AUTOSAR XML (schema 4-2-1)
standard types defined: float32, float64, sint8, sint16, sint32, uint8, uint16, uint32, boolean, dtRef_VOID, Float32, Boolean, UInt32, UInt8, UInt16
package /FoundationPkg/FoundationArchitecturePkg
  5 x constant specification:
    iColumnData_ColumnTorque_Init: value-spec={short-label=iColumnData_ColumnTorque_Init, fields=[0 Nm_Unit, 0 NmPerSec_Unit, 0]}
    iColumnData_SteeringPositionLower_Init: value-spec={short-label=iColumnData_SteeringPositionLower_Init, fields=[0 Degrees_Unit, 0]}
    iColumnData_ColumnVelocity_Init: value-spec={short-label=iColumnData_ColumnVelocity_Init, fields=[0 RevsPerSec_Unit, 0 RevsPerSec_Unit, 0]}
    iColumnData_SteeringPositionUpper_Init: value-spec={short-label=iColumnData_SteeringPositionUpper_Init, fields=[0 Degrees_Unit, 0]}
    iColumnData_ColumnPositionLower_Init: value-spec={short-label=iColumnData_ColumnPositionLower_Init, fields=[0 Degrees_Unit, 0]}
  sender receiver interface iColumnData
    5 x data, all with sw-calibration-access=READ-ONLY:
      ColumnTorque: type=tInputTorque, init-value=constant-reference=iColumnData_ColumnTorque_Init
      SteeringPositionLower: type=tColumnPosition, init-value=constant-reference=iColumnData_SteeringPositionLower_Init
      ColumnVelocity: type=tColumnVelocity, init-value=constant-reference=iColumnData_ColumnVelocity_Init
      SteeringPositionUpper: type=tColumnPosition, init-value=constant-reference=iColumnData_SteeringPositionUpper_Init
      ColumnPositionLower: type=tMechanicalMotorPosition, init-value=constant-reference=iColumnData_ColumnPositionLower_Init
  constant specification iTorque_Torque_Init: value-spec={short-label=iTorque_Torque_Init, fields=[0 Nm_Unit, 0 NmPerSec_Unit, 0]}
  sender receiver interface iTorque
    data Torque: sw-calibration-access=READ-ONLY, type=tInputTorque, init-value=constant-reference=iTorque_Torque_Init
  constant specification iAngle_Angle_Init: value-spec={short-label=iAngle_Angle_Init, fields=[0 Degrees_Unit, 0]}
  sender receiver interface iAngle
    data Angle: sw-calibration-access=READ-ONLY, type=tSensorAngle, init-value=constant-reference=iAngle_Angle_Init
  constant specification iPinionData_PinionPosition_Init: value-spec={short-label=iPinionData_PinionPosition_Init, fields=[0 Degrees_Unit, 0]}
  constant specification iPinionData_PinionVelocity_Init: value-spec={short-label=iPinionData_PinionVelocity_Init, fields=[0 RevsPerSec_Unit, 0 RevsPerSec_Unit, 0]}
  sender receiver interface iPinionData
    data PinionPosition: sw-calibration-access=READ-ONLY, type=tPinionPosition, init-value=constant-reference=iPinionData_PinionPosition_Init
    data PinionVelocity: sw-calibration-access=READ-ONLY, type=tColumnVelocity, init-value=constant-reference=iPinionData_PinionVelocity_Init
  constant specification iVehicleData_VehicleSpeed_Init: value-spec={short-label=iVehicleData_VehicleSpeed_Init, fields=[0 Kph_Unit, 0, 0]}
  constant specification iVehicleData_SteeringAngle_Init: value-spec={short-label=iVehicleData_SteeringAngle_Init, fields=[0 Degrees_Unit, 0]}
  sender receiver interface iVehicleData
    data VehicleSpeed: sw-calibration-access=READ-ONLY, type=tVehicleSpd, init-value=constant-reference=iVehicleData_VehicleSpeed_Init
    data SteeringAngle: sw-calibration-access=READ-ONLY, type=tColumnPosition, init-value=constant-reference=iVehicleData_SteeringAngle_Init
  5 x constant specification:
    iTuneData_VEHICLE_SPEED_BREAKPOINTS_Init: value-spec=[0.0, 5.0, 10.0, 15.0, 25.0, 35.0, 50.0, 70.0, 90.0, 120.0, 150.0, 190.0]
    iTuneData_TIME_SFB_Init: value-spec=20
    iTuneData_ANGLE_MEASUREMENT_RANGE_Init: value-spec=1800.0
    iTuneData_MAX_NVM_WRITE_WAIT_TIME_Init: value-spec=100
    iTuneData_MAX_NVM_WRITE_ATTEMPTS_Init: value-spec=3
  parameter interface iTuneData
    5 x parameter data prototype, all with sw-addr-method=VehicleTune, sw-calibration-access=READ-WRITE:
      VEHICLE_SPEED_BREAKPOINTS: category=ARRAY, type=tVspdBkpts_0_0_to_255_0, init-value=constant-reference=iTuneData_VEHICLE_SPEED_BREAKPOINTS_Init
      TIME_SFB: category=VALUE, type=ms_20_to_20, init-value=constant-reference=iTuneData_TIME_SFB_Init
      ANGLE_MEASUREMENT_RANGE: category=VALUE, type=Degrees_0_0_to_1800_0, init-value=constant-reference=iTuneData_ANGLE_MEASUREMENT_RANGE_Init
      MAX_NVM_WRITE_WAIT_TIME: category=VALUE, type=ms, init-value=constant-reference=iTuneData_MAX_NVM_WRITE_WAIT_TIME_Init  # Time to wait for NVM write to complete
      MAX_NVM_WRITE_ATTEMPTS: category=VALUE, type=UInt8, init-value=constant-reference=iTuneData_MAX_NVM_WRITE_ATTEMPTS_Init  # Maximum number of times to attempt NVM write.
  client server interface iRack
    8 x operation:
      getMaxPhysicalAssist
        arg maxPhysicalAssist: type=Nm, direction=OUT
      initialisationColumnAngle
        arg pinionAngle: type=Degrees, direction=IN
      translateColumnAngleToRackPosition
        arg pinionAngle: type=Degrees, direction=IN
        arg rackPosition: type=mm, direction=OUT
      translateColumnTorqueToRackForce
        arg columnTorque: type=Nm, direction=IN
        arg rackForce: type=kN, direction=OUT
      translateRackPositionToColumnAngle
        arg rackPosition: type=mm, direction=IN
        arg columnAngle: type=Degrees, direction=OUT
      translateRackForceToColumnTorque
        arg rackForce: type=kN, direction=IN
        arg columnTorque: type=Nm, direction=OUT
      translateColumnVelocityToRackVelocity
        arg columnVelocity: type=DegreesPerSec, direction=IN
        arg rackVelocity: type=mmPerSec, direction=OUT
      translateRackVelocityToColumnVelocity
        arg rackVelocity: type=mmPerSec, direction=IN
        arg columnVelocity: type=DegreesPerSec, direction=OUT
  constant specification iStraightAheadOffset_StraightAheadOffset_Init: value-spec={short-label=iStraightAheadOffset_StraightAheadOffset_Init, fields=[0 Degrees_Unit, 0]}
  sender receiver interface iStraightAheadOffset
    data StraightAheadOffset: sw-calibration-access=READ-ONLY, type=tStraightAheadOffset, init-value=constant-reference=iStraightAheadOffset_StraightAheadOffset_Init
package /FoundationPkg/FoundationArchitecturePkg/FoundationEpsAbstractionPkg
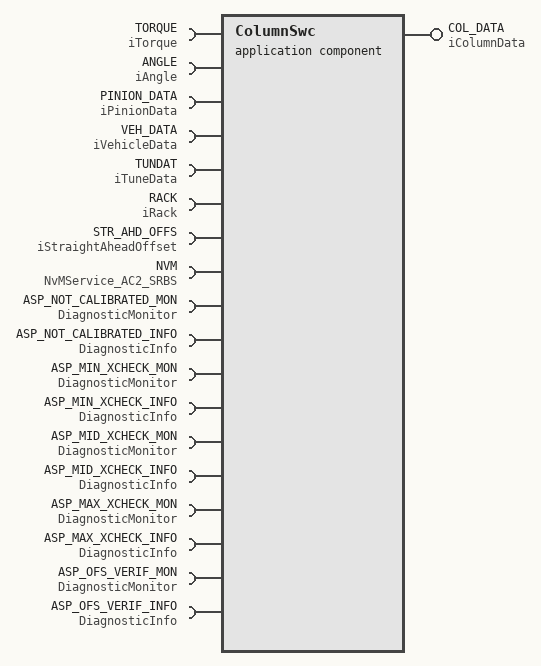
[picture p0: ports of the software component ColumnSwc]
  application sw component type ColumnSwc  # Model of the EPS steering column producing the column torque, positionand velocitysignals to the EPS system. The model shall take into account the physical characteristics of the steering column such as the torsion bar where they impact the output signals.
    provide port COL_DATA: provided-interface=iColumnData  # Output column data (torque, position and velocity)
      provided-com-specs:
        data-element=ColumnTorque, init-value=constant-reference=iColumnData_ColumnTorque_Init
        data-element=SteeringPositionLower, init-value=constant-reference=iColumnData_SteeringPositionLower_Init
        data-element=ColumnVelocity, init-value=constant-reference=iColumnData_ColumnVelocity_Init
        data-element=SteeringPositionUpper, init-value=constant-reference=iColumnData_SteeringPositionUpper_Init
        data-element=ColumnPositionLower, init-value=constant-reference=iColumnData_ColumnPositionLower_Init
    18 x require port:
      TORQUE: nonqueued-receiver-com-spec{data-element=Torque, init-value=constant-reference=iTorque_Torque_Init}, required-interface=iTorque  # Torque data received from the column torque sensor.
      ANGLE: nonqueued-receiver-com-spec{data-element=Angle, init-value=constant-reference=iAngle_Angle_Init}, required-interface=iAngle  # Angle data received from the column angle sensor.
      PINION_DATA: required-interface=iPinionData  # Data for the pinion position derived from the motor position
        required-com-specs:
          data-element=PinionPosition, init-value=constant-reference=iPinionData_PinionPosition_Init
          data-element=PinionVelocity, init-value=constant-reference=iPinionData_PinionVelocity_Init
      VEH_DATA: required-interface=iVehicleData  # Data regarding the vehicle dynamic state (speed, steering angle derived from the wheel speeds etc).
        required-com-specs:
          data-element=VehicleSpeed, init-value=constant-reference=iVehicleData_VehicleSpeed_Init
          data-element=SteeringAngle, init-value=constant-reference=iVehicleData_SteeringAngle_Init
      TUNDAT: required-interface=iTuneData
        required-com-specs:
          init-value=constant-reference=iTuneData_VEHICLE_SPEED_BREAKPOINTS_Init, parameter=VEHICLE_SPEED_BREAKPOINTS
          init-value=constant-reference=iTuneData_TIME_SFB_Init, parameter=TIME_SFB
          init-value=constant-reference=iTuneData_ANGLE_MEASUREMENT_RANGE_Init, parameter=ANGLE_MEASUREMENT_RANGE
          init-value=constant-reference=iTuneData_MAX_NVM_WRITE_WAIT_TIME_Init, parameter=MAX_NVM_WRITE_WAIT_TIME
          init-value=constant-reference=iTuneData_MAX_NVM_WRITE_ATTEMPTS_Init, parameter=MAX_NVM_WRITE_ATTEMPTS
      RACK: required-interface=iRack  # Set the initial column angle at startup.
      STR_AHD_OFFS: nonqueued-receiver-com-spec{data-element=StraightAheadOffset, init-value=constant-reference=iStraightAheadOffset_StraightAheadOffset_Init}, required-interface=iStraightAheadOffset  # Offset between the angle provided by the column angle sensor and the vehicle straight ahead position.
      NVM: required-interface=NvMService_AC2_SRBS
      ASP_NOT_CALIBRATED_MON: required-interface=DiagnosticMonitor
      ASP_NOT_CALIBRATED_INFO: required-interface=DiagnosticInfo
      ASP_MIN_XCHECK_MON: required-interface=DiagnosticMonitor
      ASP_MIN_XCHECK_INFO: required-interface=DiagnosticInfo
      ASP_MID_XCHECK_MON: required-interface=DiagnosticMonitor
      ASP_MID_XCHECK_INFO: required-interface=DiagnosticInfo
      ASP_MAX_XCHECK_MON: required-interface=DiagnosticMonitor
      ASP_MAX_XCHECK_INFO: required-interface=DiagnosticInfo
      ASP_OFS_VERIF_MON: required-interface=DiagnosticMonitor
      ASP_OFS_VERIF_INFO: required-interface=DiagnosticInfo
    behavior ColumnSwc_IB: data-type-mapping=MappingSet, handle-termination-and-restart=NO-SUPPORT
      ar-typed-per-instance-memorys:
        data ColumnNvm: category=STRUCTURE, type=tColumnNvm
      4 x timing event:
        Event_calculateColumnTorque: start-on-event=ColumnSwc_calculateColumnTorque, period=0.001
        Event_calculateColumnAngle: start-on-event=ColumnSwc_calculateColumnAngle, period=0.001
        Event_calculateColumnVelocity: start-on-event=ColumnSwc_calculateColumnVelocity, period=0.001
        Event_verifyAbsoluteSteeringPosition: start-on-event=ColumnSwc_verifyAbsoluteSteeringPosition, period=0.004
      init event Event_initialiser_Init: start-on-event=ColumnSwc_initialiser
      implicit-inter-runnable-variables:
        9 x data:
          SteeringPositionLower_Value: type=Degrees, init-value=constant-reference=SteeringPositionLower_Value_Init
          SteeringPositionLower_Qf: type=tQualityFactor, init-value=constant-reference=SteeringPositionLower_Qf_Init
          AspVerificationStatus: sw-calibration-access=READ-ONLY, type=tAspVerificationSts, init-value=constant-reference=ColumnSwc_AspVerificationStatus_Init
          ColumnTorque_Value: type=Nm, init-value=constant-reference=ColumnTorque_Value_Init
          ColumnTorque_Derivative: type=NmPerSec, init-value=constant-reference=ColumnTorque_Derivative_Init
          ColumnTorque_Qf: type=tQualityFactor, init-value=constant-reference=ColumnTorque_Qf_Init
          ColumnVelocity_Filtered: type=RevsPerSec, init-value=constant-reference=ColumnVelocity_Filtered_Init
          ColumnVelocity_Unfiltered: type=RevsPerSec, init-value=constant-reference=ColumnVelocity_Unfiltered_Init
          ColumnVelocity_Qf: type=tQualityFactor, init-value=constant-reference=ColumnVelocity_Qf_Init
      per-instance-parameters:
        12 x parameter data prototype, all with category=VALUE, sw-addr-method=VehicleTune, sw-calibration-access=READ-WRITE:
          TBAR_STIFFNESS: type=NmPerDegree_0_1_to_10_0, init-value=constant-reference=LocalCalibration_TBAR_STIFFNESS_Init
          SIGNAL_LATENCY_COMPENSATION_GAIN: type=Float32_n3_0_to_3_0, init-value=constant-reference=LocalCalibration_SIGNAL_LATENCY_COMPENSATION_GAIN_Init
          INITIAL_SP_TORQUE_THRESHOLD: type=Nm_0_to_10, init-value=constant-reference=LocalCalibration_INITIAL_SP_TORQUE_THRESHOLD_Init
          INITIAL_SP_COLUMN_VELOCITY_THRESHOLD: type=RevsPerSec_0_to_100, init-value=constant-reference=LocalCalibration_INITIAL_SP_COLUMN_VELOCITY_THRESHOLD_Init
          SP_VERIFICATION_NEGATE_THRESHOLD: type=Degrees_0_to_15, init-value=constant-reference=LocalCalibration_SP_VERIFICATION_NEGATE_THRESHOLD_Init
          SP_VERIFICATION_AFFIRM_THRESHOLD: type=Degrees_0_to_15, init-value=constant-reference=LocalCalibration_SP_VERIFICATION_AFFIRM_THRESHOLD_Init
          PRIMARY_ASP_SOURCE: type=tPrimaryAspSource, init-value=constant-reference=LocalCalibration_PRIMARY_ASP_SOURCE_Init  # Which sensor is to be used as primary source for ASP.
          ANGLE_SENSOR_POSITION: type=tAngleSensorPosition, init-value=constant-reference=LocalCalibration_ANGLE_SENSOR_POSITION_Init  # Location of the angle sensor, above or below the torsion bar.
          SA_VERIFY_NUM_INTGL_INST: type=UInt16_1_to_100, init-value=constant-reference=LocalCalibration_SA_VERIFY_NUM_INTGL_INST_Init  # Tumber of learning instances to be used for averaging the deviation between calculated (based on sensor signals) and estimated (based on wheel speeds) .
          SA_VERIFY_STORED_POSN_DEV_THD: type=Degrees_0_to_1000, init-value=constant-reference=LocalCalibration_SA_VERIFY_STORED_POSN_DEV_THD_Init  # Threshold to check last stored ASP with key-on ASP to detect key-off steering.
          SA_VERIFY_AVRG_DEV_THD: type=Degrees_0_to_1000, init-value=constant-reference=LocalCalibration_SA_VERIFY_AVRG_DEV_THD_Init  # Threshold to check last stored ASP with key-on ASP to detect key-off steering.
          ASP_OFS_VERIFICATION_ACTVD: type=Boolean, init-value=constant-reference=LocalCalibration_ASP_OFS_VERIFICATION_ACTVD_Init
      5 x runnable:
        ColumnSwc_calculateColumnTorque: symbol=Column_calculateColumnTorque  # Calculate the column torque from the column sensor torque input.
          data-read-access:
            access R_TORQUE_Torque: accessed-variable=TORQUE.Torque
          data-write-access:
            access W_COL_DATA_ColumnTorque: accessed-variable=COL_DATA.ColumnTorque
          parameter access TIME_SFB: accessed-parameter=TUNDAT.TIME_SFB
          written-local-variables:
            access WV_ColumnTorque_Value: accessed-variable=ColumnTorque_Value
            access WV_ColumnTorque_Derivative: accessed-variable=ColumnTorque_Derivative
            access WV_ColumnTorque_Qf: accessed-variable=ColumnTorque_Qf
        ColumnSwc_calculateColumnAngle: symbol=Column_calculateColumnAngle  # Column offsets the raw angle received from the angle sensor with the calibrated straight ahead position to provide an absolute steering position. Column torque is used to compensate for torsion bar deflection. A cross check is made between the column position determined from the motor position sensor and the value from the column sensor to provide an ASIL D ASP value.
          data-read-access:
            access R_PINION_DATA_PinionPosition: accessed-variable=PINION_DATA.PinionPosition
            access R_ANGLE_Angle: accessed-variable=ANGLE.Angle
            access R_STR_AHD_OFFS_StraightAheadOffset: accessed-variable=STR_AHD_OFFS.StraightAheadOffset
          data-write-access:
            access W_COL_DATA_SteeringPositionLower: accessed-variable=COL_DATA.SteeringPositionLower
            access W_COL_DATA_SteeringPositionUpper: accessed-variable=COL_DATA.SteeringPositionUpper
            access W_COL_DATA_ColumnPositionLower: accessed-variable=COL_DATA.ColumnPositionLower
          4 x parameter access:
            TBAR_STIFFNESS: accessed-parameter=TBAR_STIFFNESS
            ANGLE_MEASUREMENT_RANGE: accessed-parameter=TUNDAT.ANGLE_MEASUREMENT_RANGE
            PRIMARY_ASP_SOURCE: accessed-parameter=PRIMARY_ASP_SOURCE
            ANGLE_SENSOR_POSITION: accessed-parameter=ANGLE_SENSOR_POSITION
          read-local-variables:
            4 x access:
              RV_AspVerificationStatus: accessed-variable=AspVerificationStatus
              RV_ColumnTorque_Value: accessed-variable=ColumnTorque_Value
              RV_ColumnTorque_Derivative: accessed-variable=ColumnTorque_Derivative
              RV_ColumnTorque_Qf: accessed-variable=ColumnTorque_Qf
          5 x sync call:
            Call_RACK_initialisationColumnAngle: operation=RACK.initialisationColumnAngle
            Call_ASP_NOT_CALIBRATED_SetEventStatus: operation=ASP_NOT_CALIBRATED_MON.SetEventStatus
            Call_ASP_NOT_CALIBRATED_ResetEventStatus: operation=ASP_NOT_CALIBRATED_MON.ResetEventDebounceStatus
            Call_ASP_NOT_CALIBRATED_GetEventStatus: operation=ASP_NOT_CALIBRATED_INFO.GetEventStatus
            Call_ASP_NOT_CALIBRATED_GetEventFailed: operation=ASP_NOT_CALIBRATED_INFO.GetEventFailed
          written-local-variables:
            access WV_SteeringPositionLower_Value: accessed-variable=SteeringPositionLower_Value
            access WV_SteeringPositionLower_Qf: accessed-variable=SteeringPositionLower_Qf
        ColumnSwc_calculateColumnVelocity: symbol=Column_calculateColumnVelocity  # Column Velocity is a read through of the pinion velocity.
          data-read-access:
            access R_PINION_DATA_PinionVelocity: accessed-variable=PINION_DATA.PinionVelocity
          data-write-access:
            access W_COL_DATA_ColumnVelocity: accessed-variable=COL_DATA.ColumnVelocity
          written-local-variables:
            access WV_ColumnVelocity_Filtered: accessed-variable=ColumnVelocity_Filtered
            access WV_ColumnVelocity_Unfiltered: accessed-variable=ColumnVelocity_Unfiltered
            access WV_ColumnVelocity_Qf: accessed-variable=ColumnVelocity_Qf
        ColumnSwc_verifyAbsoluteSteeringPosition: symbol=Column_verifyAbsoluteSteeringPosition  # Perform a cross check between the absolute steering position produced from the column angle sensor against the column angle derived from the motor position sensor. Report the validity of the cross check to the calculate column angle runnable.
          data-read-access:
            access R_PINION_DATA_PinionPosition: accessed-variable=PINION_DATA.PinionPosition
            access R_VEH_DATA_SteeringAngle: accessed-variable=VEH_DATA.SteeringAngle
            access R_ANGLE_Angle: accessed-variable=ANGLE.Angle
          9 x parameter access:
            INITIAL_SP_COLUMN_VELOCITY_THRESHOLD: accessed-parameter=INITIAL_SP_COLUMN_VELOCITY_THRESHOLD
            INITIAL_SP_TORQUE_THRESHOLD: accessed-parameter=INITIAL_SP_TORQUE_THRESHOLD
            SIGNAL_LATENCY_COMPENSATION_GAIN: accessed-parameter=SIGNAL_LATENCY_COMPENSATION_GAIN
            SP_VERIFICATION_AFFIRM_THRESHOLD: accessed-parameter=SP_VERIFICATION_AFFIRM_THRESHOLD
            SP_VERIFICATION_NEGATE_THRESHOLD: accessed-parameter=SP_VERIFICATION_NEGATE_THRESHOLD
            SA_VERIFY_AVRG_DEV_THD: accessed-parameter=SA_VERIFY_AVRG_DEV_THD
            SA_VERIFY_NUM_INTGL_INST: accessed-parameter=SA_VERIFY_NUM_INTGL_INST
            SA_VERIFY_STORED_POSN_DEV_THD: accessed-parameter=SA_VERIFY_STORED_POSN_DEV_THD
            ASP_OFS_VERIFICATION_ACTVD: accessed-parameter=ASP_OFS_VERIFICATION_ACTVD
          read-local-variables:
            8 x access:
              RV_ColumnVelocity_Filtered: accessed-variable=ColumnVelocity_Filtered
              RV_ColumnVelocity_Unfiltered: accessed-variable=ColumnVelocity_Unfiltered
              RV_ColumnVelocity_Qf: accessed-variable=ColumnVelocity_Qf
              RV_ColumnTorque_Value: accessed-variable=ColumnTorque_Value
              RV_ColumnTorque_Derivative: accessed-variable=ColumnTorque_Derivative
              RV_ColumnTorque_Qf: accessed-variable=ColumnTorque_Qf
              RV_SteeringPositionLower_Value: accessed-variable=SteeringPositionLower_Value
              RV_SteeringPositionLower_Qf: accessed-variable=SteeringPositionLower_Qf
          16 x sync call:
            Call_ASP_MAX_XCHECK_SetEventStatus: operation=ASP_MAX_XCHECK_MON.SetEventStatus
            Call_ASP_MAX_XCHECK_ResetEventStatus: operation=ASP_MAX_XCHECK_MON.ResetEventDebounceStatus
            Call_ASP_MAX_XCHECK_GetEventStatus: operation=ASP_MAX_XCHECK_INFO.GetEventStatus
            Call_ASP_MAX_XCHECK_GetEventFailed: operation=ASP_MAX_XCHECK_INFO.GetEventFailed
            Call_ASP_MID_XCHECK_SetEventStatus: operation=ASP_MID_XCHECK_MON.SetEventStatus
            Call_ASP_MID_XCHECK_ResetEventStatus: operation=ASP_MID_XCHECK_MON.ResetEventDebounceStatus
            Call_ASP_MID_XCHECK_GetEventStatus: operation=ASP_MID_XCHECK_INFO.GetEventStatus
            Call_ASP_MID_XCHECK_GetEventFailed: operation=ASP_MID_XCHECK_INFO.GetEventFailed
            Call_ASP_MIN_XCHECK_SetEventStatus: operation=ASP_MIN_XCHECK_MON.SetEventStatus
            Call_ASP_MIN_XCHECK_ResetEventStatus: operation=ASP_MIN_XCHECK_MON.ResetEventDebounceStatus
            Call_ASP_MIN_XCHECK_GetEventStatus: operation=ASP_MIN_XCHECK_INFO.GetEventStatus
            Call_ASP_MIN_XCHECK_GetEventFailed: operation=ASP_MIN_XCHECK_INFO.GetEventFailed
            Call_ASP_OFS_VERIF_SetEventStatus: operation=ASP_OFS_VERIF_MON.SetEventStatus
            Call_ASP_OFS_VERIF_ResetEventStatus: operation=ASP_OFS_VERIF_MON.ResetEventDebounceStatus
            Call_ASP_OFS_VERIF_GetEventStatus: operation=ASP_OFS_VERIF_INFO.GetEventStatus
            Call_ASP_OFS_VERIF_GetEventFailed: operation=ASP_OFS_VERIF_INFO.GetEventFailed
          written-local-variables:
            access WV_AspVerificationStatus: accessed-variable=AspVerificationStatus
        ColumnSwc_initialiser: symbol=Column_initialiser
          sync call Call_NVM_SetRamBlockStatus: operation=NVM.SetRamBlockStatus
      11 x swc service dependency:
        SwcNv_ColumnNvm: assigned-datas=role-based-data-assignment={role=ramBlock, used-data-element=ColumnNvm}, assigned-ports=role-based-port-assignment={port-prototype=NVM, role=ColumnNvm}
          service-needs:
            nv block needs SwcNv_ColumnNvm: calc-ram-block-crc=true, check-static-block-id=false, ram-block-status-control=NV-RAM-MANAGER, readonly=false, reliability=ERROR-DETECTION, resistant-to-changed-sw=true, restore-at-start=true, store-at-shutdown=true, store-cyclic=false, store-emergency=false, store-immediate=false, use-auto-validation-at-shut-down=false, use-crc-comp-mechanism=true, write-only-once=false, write-verification=false
        Monitor_ASP_NOT_CALIBRATED: assigned-ports=role-based-port-assignment={port-prototype=ASP_NOT_CALIBRATED_MON, role=DiagnosticMonitor}
          service-needs:
            diagnostic event needs EventNeed_ASP_NOT_CALIBRATED
        Info_ASP_NOT_CALIBRATED: assigned-ports=role-based-port-assignment={port-prototype=ASP_NOT_CALIBRATED_INFO, role=DiagnosticInfo}
          service-needs:
            diagnostic event info needs InfoNeed_ASP_NOT_CALIBRATED
        Monitor_ASP_MIN_XCHECK: assigned-ports=role-based-port-assignment={port-prototype=ASP_MIN_XCHECK_MON, role=DiagnosticMonitor}
          service-needs:
            diagnostic event needs EventNeed_ASP_MIN_XCHECK
        Info_ASP_MIN_XCHECK: assigned-ports=role-based-port-assignment={port-prototype=ASP_MIN_XCHECK_INFO, role=DiagnosticInfo}
          service-needs:
            diagnostic event info needs InfoNeed_ASP_MIN_XCHECK
        Monitor_ASP_MID_XCHECK: assigned-ports=role-based-port-assignment={port-prototype=ASP_MID_XCHECK_MON, role=DiagnosticMonitor}
          service-needs:
            diagnostic event needs EventNeed_ASP_MID_XCHECK
        Info_ASP_MID_XCHECK: assigned-ports=role-based-port-assignment={port-prototype=ASP_MID_XCHECK_INFO, role=DiagnosticInfo}
          service-needs:
            diagnostic event info needs InfoNeed_ASP_MID_XCHECK
        Monitor_ASP_MAX_XCHECK: assigned-ports=role-based-port-assignment={port-prototype=ASP_MAX_XCHECK_MON, role=DiagnosticMonitor}
          service-needs:
            diagnostic event needs EventNeed_ASP_MAX_XCHECK
        Info_ASP_MAX_XCHECK: assigned-ports=role-based-port-assignment={port-prototype=ASP_MAX_XCHECK_INFO, role=DiagnosticInfo}
          service-needs:
            diagnostic event info needs InfoNeed_ASP_MAX_XCHECK
        Monitor_ASP_OFS_VERIF: assigned-ports=role-based-port-assignment={port-prototype=ASP_OFS_VERIF_MON, role=DiagnosticMonitor}
          service-needs:
            diagnostic event needs EventNeed_ASP_OFS_VERIF
        Info_ASP_OFS_VERIF: assigned-ports=role-based-port-assignment={port-prototype=ASP_OFS_VERIF_INFO, role=DiagnosticInfo}
          service-needs:
            diagnostic event info needs InfoNeed_ASP_OFS_VERIF
  impl type tColumnNvm: category=STRUCTURE
    element LastSteeringPosition: implementation-data-type=tColumnPosition
  13 x constant specification:
    ColumnSwc_AspVerificationStatus_Init: value-spec=0
    LocalCalibration_TBAR_STIFFNESS_Init: value-spec=3.2
    LocalCalibration_SIGNAL_LATENCY_COMPENSATION_GAIN_Init: value-spec=0.36
    LocalCalibration_INITIAL_SP_TORQUE_THRESHOLD_Init: value-spec=0.5
    LocalCalibration_INITIAL_SP_COLUMN_VELOCITY_THRESHOLD_Init: value-spec=0.0625
    LocalCalibration_SP_VERIFICATION_NEGATE_THRESHOLD_Init: value-spec=15.0
    LocalCalibration_SP_VERIFICATION_AFFIRM_THRESHOLD_Init: value-spec=15.0
    LocalCalibration_PRIMARY_ASP_SOURCE_Init: value-spec=0
    LocalCalibration_ANGLE_SENSOR_POSITION_Init: value-spec=1
    LocalCalibration_SA_VERIFY_NUM_INTGL_INST_Init: value-spec=100
    LocalCalibration_SA_VERIFY_STORED_POSN_DEV_THD_Init: value-spec=15.0
    LocalCalibration_SA_VERIFY_AVRG_DEV_THD_Init: value-spec=45.0
    LocalCalibration_ASP_OFS_VERIFICATION_ACTVD_Init: value-spec=0
package /FoundationPkg/FoundationArchitecturePkg/FoundationEpsAbstractionPkg/ApplicationTypesPkg
  application record data type tColumnNvm: category=STRUCTURE
    application record element LastSteeringPosition: category=STRUCTURE, type=tColumnPosition
package /FoundationPkg/FoundationArchitecturePkg/FoundationTypes
  unit Nm_Unit
  impl type Nm: implementation-data-type=Float32
  unit NmPerSec_Unit
  impl type NmPerSec: implementation-data-type=Float32
  compu method tQualityFactor_Compu: 0=QF_UNINITIALIZED, 0=QF_UNINITIALISED, 1=QF_UNAVAILABLE, 2=QF_DEGRADED, 3=QF_FULL
  impl type tQualityFactor: category=VALUE, base-type=sint32, compu-method=tQualityFactor_Compu
  impl type tInputTorque: category=STRUCTURE
    element Value: implementation-data-type=Nm
    element Derivative: implementation-data-type=NmPerSec
    element Qf: implementation-data-type=tQualityFactor
  unit Degrees_Unit
  impl type Degrees: implementation-data-type=Float32
  impl type tColumnPosition: category=STRUCTURE
    element Value: implementation-data-type=Degrees
    element Qf: implementation-data-type=tQualityFactor
  unit RevsPerSec_Unit
  impl type RevsPerSec: implementation-data-type=Float32
  impl type tColumnVelocity: category=STRUCTURE
    element Filtered: implementation-data-type=RevsPerSec
    element Unfiltered: implementation-data-type=RevsPerSec
    element Qf: implementation-data-type=tQualityFactor
  impl type tMechanicalMotorPosition: category=STRUCTURE
    element Value: implementation-data-type=Degrees
    element Qf: implementation-data-type=tQualityFactor
  impl type tSensorAngle: category=STRUCTURE
    element Value: implementation-data-type=Degrees
    element Qf: implementation-data-type=tQualityFactor
  impl type tPinionPosition: category=STRUCTURE
    element Value: implementation-data-type=Degrees
    element Qf: implementation-data-type=tQualityFactor
  unit Kph_Unit
  impl type Kph: implementation-data-type=Float32
  impl type tVehicleSpd: category=STRUCTURE
    element Filtered: implementation-data-type=Kph
    element Moving: implementation-data-type=Boolean
    element Qf: implementation-data-type=tQualityFactor
  impl type tVspdBkpts: category=ARRAY
    element Element: array-size=12, array-size-semantics=FIXED-SIZE, implementation-data-type=Float32
  unit ms_Unit
  impl type ms: implementation-data-type=UInt32
  unit mm_Unit
  impl type mm: implementation-data-type=Float32
  unit kN_Unit
  impl type kN: implementation-data-type=Float32
  unit DegreesPerSec_Unit
  impl type DegreesPerSec: implementation-data-type=Float32
  unit mmPerSec_Unit
  impl type mmPerSec: implementation-data-type=Float32
  impl type tStraightAheadOffset: category=STRUCTURE
    element Value: implementation-data-type=Degrees
    element Qf: implementation-data-type=tQualityFactor
  constant specification SteeringPositionLower_Value_Init: value-spec=0.0
  constant specification SteeringPositionLower_Qf_Init: value-spec=0
  impl type tAspVerificationSts: category=VALUE, base-type=sint32, compu {0=ASP_VERIFYING, 1=ASP_FAULTY, 2=ASP_VERIFIED}
  6 x constant specification:
    ColumnTorque_Value_Init: value-spec=0.0
    ColumnTorque_Derivative_Init: value-spec=0.0
    ColumnTorque_Qf_Init: value-spec=0
    ColumnVelocity_Filtered_Init: value-spec=0.0
    ColumnVelocity_Unfiltered_Init: value-spec=0.0
    ColumnVelocity_Qf_Init: value-spec=0
  unit NmPerDegree_Unit
  impl type NmPerDegree: implementation-data-type=Float32
  impl type tPrimaryAspSource: category=VALUE, base-type=sint32, compu {0=ASP_MPS, 1=ASP_TAS}
  impl type tAngleSensorPosition: category=VALUE, base-type=sint32, compu {0=AS_NOT_FITTED, 1=AS_LOWER, 2=AS_UPPER}
package /FoundationPkg/FoundationArchitecturePkg/FoundationTypes/ApplicationTypesPkg
  4 x app type, all with category=VALUE:
    Nm: compu {identical; unit Nm_Unit}, range phys -10..10, unit=Nm_Unit
    Float32: compu {identical}
    NmPerSec: compu {identical; unit NmPerSec_Unit}, range phys -2048..2048, unit=NmPerSec_Unit  # Rate of change of torque
    tQualityFactor: base-type=sint32, compu-method=tQualityFactor_Compu
  application record data type tInputTorque: category=STRUCTURE
    application record element Value: category=VALUE, type=Nm
    application record element Derivative: category=VALUE, type=NmPerSec
    application record element Qf: category=VALUE, type=tQualityFactor
  app type Degrees_n720_0_to_720_0: category=VALUE, compu {identical; unit Degrees_Unit}, range phys -720..720, unit=Degrees_Unit
  application record data type tColumnPosition: category=STRUCTURE  # Measument of the Column position in degrees with range -720 - +720.
    application record element Value: category=VALUE, type=Degrees_n720_0_to_720_0
    application record element Qf: category=VALUE, type=tQualityFactor
  app type Degrees: category=VALUE, compu {identical; unit Degrees_Unit}, unit=Degrees_Unit
  app type RevsPerSec: category=VALUE, compu {identical; unit RevsPerSec_Unit}, unit=RevsPerSec_Unit
  application record data type tColumnVelocity: category=STRUCTURE
    application record element Filtered: category=VALUE, type=RevsPerSec
    application record element Unfiltered: category=VALUE, type=RevsPerSec
    application record element Qf: category=VALUE, type=tQualityFactor
  app type Degrees_n29520_to_29520: category=VALUE, compu {identical; unit Degrees_Unit}, range phys -29520..29520, unit=Degrees_Unit
  application record data type tMechanicalMotorPosition: category=STRUCTURE
    application record element Value: category=VALUE, type=Degrees_n29520_to_29520
    application record element Qf: category=VALUE, type=tQualityFactor
  app type Degrees_0_0_to_1800_0: category=VALUE, compu {identical; unit Degrees_Unit}, range phys 0..1800, unit=Degrees_Unit
  application record data type tSensorAngle: category=STRUCTURE
    application record element Value: category=VALUE, type=Degrees_0_0_to_1800_0
    application record element Qf: category=VALUE, type=tQualityFactor
  app type Degrees_n1440_0_to_1440_0: category=VALUE, compu {identical; unit Degrees_Unit}, range phys -1440..1440, unit=Degrees_Unit
  application record data type tPinionPosition: category=STRUCTURE  # Measument of the relative pinion position in degrees with range -1440 - +1440. Used for relative position determined from the motor position (has greater range than the column position).
    application record element Value: category=VALUE, type=Degrees_n1440_0_to_1440_0
    application record element Qf: category=VALUE, type=tQualityFactor
  app type Kph_0_to_400: category=VALUE, compu {identical; unit Kph_Unit}, range phys 0..400, unit=Kph_Unit
  app type Boolean: category=VALUE
  application record data type tVehicleSpd: category=STRUCTURE
    application record element Filtered: category=VALUE, type=Kph_0_to_400
    application record element Moving: category=VALUE, type=Boolean
    application record element Qf: category=VALUE, type=tQualityFactor
  app type Kph: category=VALUE, compu {identical; unit Kph_Unit}, unit=Kph_Unit
  app type Float32_0_0_to_255_0: category=VALUE, compu {identical}, range phys 0..255
  application array data type tVspdBkpts_0_0_to_255_0: category=ARRAY
    element Element: category=VALUE, type=Float32_0_0_to_255_0, array-size-semantics=FIXED-SIZE, max-number-of-elements=12
  8 x app type, all with category=VALUE:
    ms_20_to_20: compu {identical; unit ms_Unit}, range phys 20, unit=ms_Unit
    UInt32: compu {identical}
    ms: compu {identical; unit ms_Unit}, unit=ms_Unit
    UInt8: compu {identical}
    mm: compu {identical; unit mm_Unit}, unit=mm_Unit
    kN: compu {identical; unit kN_Unit}, unit=kN_Unit
    DegreesPerSec: compu {identical; unit DegreesPerSec_Unit}, unit=DegreesPerSec_Unit
    mmPerSec: compu {identical; unit mmPerSec_Unit}, unit=mmPerSec_Unit
  application record data type tStraightAheadOffset: category=STRUCTURE
    application record element Value: category=VALUE, type=Degrees
    application record element Qf: category=VALUE, type=tQualityFactor
  10 x app type, all with category=VALUE:
    tAspVerificationSts: base-type=sint32, compu {0=ASP_VERIFYING, 1=ASP_FAULTY, 2=ASP_VERIFIED}
    NmPerDegree_0_1_to_10_0: compu {identical; unit NmPerDegree_Unit}, range phys 0.1..10, unit=NmPerDegree_Unit  # Unit of stiffness
    Float32_n3_0_to_3_0: compu {identical}, range phys -3..3
    Nm_0_to_10: compu {identical; unit Nm_Unit}, range phys 0..10, unit=Nm_Unit
    RevsPerSec_0_to_100: compu {identical; unit RevsPerSec_Unit}, range phys 0..100, unit=RevsPerSec_Unit
    Degrees_0_to_15: compu {identical; unit Degrees_Unit}, range phys 0..15, unit=Degrees_Unit
    tPrimaryAspSource: base-type=sint32, compu {0=ASP_MPS, 1=ASP_TAS}
    tAngleSensorPosition: base-type=sint32, compu {0=AS_NOT_FITTED, 1=AS_LOWER, 2=AS_UPPER}  # Position of the column angle sensor relative to the torsion bar.
    UInt16_1_to_100: compu {identical}, range phys 1..100
    Degrees_0_to_1000: compu {identical; unit Degrees_Unit}, range phys 0..1000, unit=Degrees_Unit
package /DataTypeMappingSets
  data type mapping set MappingSet
    data-type-maps:
      application-data-type=Float32, implementation-data-type=Float32
      application-data-type=Nm, implementation-data-type=Nm
      application-data-type=NmPerSec, implementation-data-type=NmPerSec
      application-data-type=tQualityFactor, implementation-data-type=tQualityFactor
      application-data-type=tInputTorque, implementation-data-type=tInputTorque
      application-data-type=Degrees_n720_0_to_720_0, implementation-data-type=Degrees
      application-data-type=Degrees, implementation-data-type=Degrees
      application-data-type=tColumnPosition, implementation-data-type=tColumnPosition
      application-data-type=RevsPerSec, implementation-data-type=RevsPerSec
      application-data-type=tColumnVelocity, implementation-data-type=tColumnVelocity
      application-data-type=Degrees_n29520_to_29520, implementation-data-type=Degrees
      application-data-type=tMechanicalMotorPosition, implementation-data-type=tMechanicalMotorPosition
      application-data-type=Degrees_0_0_to_1800_0, implementation-data-type=Degrees
      application-data-type=tSensorAngle, implementation-data-type=tSensorAngle
      application-data-type=Degrees_n1440_0_to_1440_0, implementation-data-type=Degrees
      application-data-type=tPinionPosition, implementation-data-type=tPinionPosition
      application-data-type=Kph_0_to_400, implementation-data-type=Kph
      application-data-type=Boolean, implementation-data-type=Boolean
      application-data-type=Kph, implementation-data-type=Kph
      application-data-type=tVehicleSpd, implementation-data-type=tVehicleSpd
      application-data-type=Float32_0_0_to_255_0, implementation-data-type=Float32
      application-data-type=tVspdBkpts_0_0_to_255_0, implementation-data-type=tVspdBkpts
      application-data-type=UInt32, implementation-data-type=UInt32
      application-data-type=ms_20_to_20, implementation-data-type=ms
      application-data-type=ms, implementation-data-type=ms
      application-data-type=UInt8, implementation-data-type=UInt8
      application-data-type=mm, implementation-data-type=mm
      application-data-type=kN, implementation-data-type=kN
      application-data-type=DegreesPerSec, implementation-data-type=DegreesPerSec
      application-data-type=mmPerSec, implementation-data-type=mmPerSec
      application-data-type=tStraightAheadOffset, implementation-data-type=tStraightAheadOffset
      application-data-type=tColumnNvm, implementation-data-type=tColumnNvm
      application-data-type=tAspVerificationSts, implementation-data-type=tAspVerificationSts
      application-data-type=NmPerDegree_0_1_to_10_0, implementation-data-type=NmPerDegree
      application-data-type=Float32_n3_0_to_3_0, implementation-data-type=Float32
      application-data-type=Nm_0_to_10, implementation-data-type=Nm
      application-data-type=RevsPerSec_0_to_100, implementation-data-type=RevsPerSec
      application-data-type=Degrees_0_to_15, implementation-data-type=Degrees
      application-data-type=tPrimaryAspSource, implementation-data-type=tPrimaryAspSource
      application-data-type=tAngleSensorPosition, implementation-data-type=tAngleSensorPosition
      application-data-type=UInt16_1_to_100, implementation-data-type=UInt16
      application-data-type=Degrees_0_to_1000, implementation-data-type=Degrees
package /SwAddrMethods
  4 x sw addr method, all with memory-allocation-keyword-policy=ADDR-METHOD-SHORT-NAME, section-type=CALIBRATION-ONLINE:
    VehicleTune
    PlatformTune
    DevelopmentTune
    SteeringTune
package /Predefined_DEV/ImplementationDataTypes
  impl type NvM_RequestResultType: compu {0=NVM_REQ_OK, 1=NVM_REQ_NOT_OK, 2=NVM_REQ_PENDING, 3=NVM_REQ_INTEGRITY_FAILED, 4=NVM_REQ_BLOCK_SKIPPED, 5=NVM_REQ_NV_INVALIDATED, 6=NVM_REQ_CANCELED, 7=NVM_REQ_REDUNDANCY_FAILED, 8=NVM_REQ_RESTORED_FROM_ROM}, implementation-data-type=uint8
package /Predefined_DEV/PortInterfaces
  client server interface NvMService_AC2_SRBS: is-service=true
    operation GetErrorStatus: possible-error=NvMService_AC2_SRBS/E_NOT_OK
      arg ErrorStatus: type=NvM_RequestResultType, direction=OUT, server-argument-impl-policy=USE-ARGUMENT-TYPE
    operation SetRamBlockStatus: possible-error=NvMService_AC2_SRBS/E_NOT_OK
      arg RamBlockStatus: type=boolean, direction=IN, server-argument-impl-policy=USE-ARGUMENT-TYPE
    error E_NOT_OK: error-code=1
package /MICROSAR/Dem_swc/DataTypes
  19 x impl type:
    Dem_EventIdType: range raw 1..65535, implementation-data-type=uint16
    Dem_RatioIdType: range raw 1..65535, implementation-data-type=uint16
    Dem_DTCStatusMaskType: range raw 0..255, implementation-data-type=uint8
    Dem_OperationCycleIdType: range raw 0..255, implementation-data-type=uint8
    Dem_DTCGroupType: range raw 0..16777215, implementation-data-type=uint32
    Dem_MaxDataValueType: category=ARRAY, sw-calibration-access=READ-ONLY
      element Dem_MaxDataValueTypeElement: array-size=1, array-size-semantics=FIXED-SIZE, implementation-data-type=uint8
    Dem_EventStatusType: compu {0=DEM_EVENT_STATUS_PASSED, 1=DEM_EVENT_STATUS_FAILED, 2=DEM_EVENT_STATUS_PREPASSED, 3=DEM_EVENT_STATUS_PREFAILED}, implementation-data-type=uint8
    Dem_EventStatusExtendedType: compu {1=DEM_UDS_STATUS_TF, 2=DEM_UDS_STATUS_TFTOC, 4=DEM_UDS_STATUS_PDTC, 8=DEM_UDS_STATUS_CDTC, 16=DEM_UDS_STATUS_TNCSLC, 32=DEM_UDS_STATUS_TFSLC, 64=DEM_UDS_STATUS_TNCTOC, 128=DEM_UDS_STATUS_WIR}, implementation-data-type=uint8
    Dem_UdsStatusByteType: compu {1=DEM_UDS_STATUS_TF, 2=DEM_UDS_STATUS_TFTOC, 4=DEM_UDS_STATUS_PDTC, 8=DEM_UDS_STATUS_CDTC, 16=DEM_UDS_STATUS_TNCSLC, 32=DEM_UDS_STATUS_TFSLC, 64=DEM_UDS_STATUS_TNCTOC, 128=DEM_UDS_STATUS_WIR}, implementation-data-type=uint8
    Dem_InitMonitorReasonType: compu {1=DEM_INIT_MONITOR_CLEAR, 2=DEM_INIT_MONITOR_RESTART, 3=DEM_INIT_MONITOR_REENABLED, 4=DEM_INIT_MONITOR_STORAGE_REENABLED}, implementation-data-type=uint8
    Dem_DTCOriginType: compu {1=DEM_DTC_ORIGIN_PRIMARY_MEMORY, 2=DEM_DTC_ORIGIN_MIRROR_MEMORY, 3=DEM_DTC_ORIGIN_PERMANENT_MEMORY, 4=DEM_DTC_ORIGIN_SECONDARY_MEMORY, 4=DEM_DTC_ORIGIN_USERDEFINED_MEMORY_10, 4=DEM_DTC_ORIGIN_USERDEFINED_MEMORY_11, 4=DEM_DTC_ORIGIN_USERDEFINED_MEMORY_12, 4=DEM_DTC_ORIGIN_USERDEFINED_MEMORY_13, 4=DEM_DTC_ORIGIN_USERDEFINED_MEMORY_14, 4=DEM_DTC_ORIGIN_USERDEFINED_MEMORY_15, 4=DEM_DTC_ORIGIN_USERDEFINED_MEMORY_16, 4=DEM_DTC_ORIGIN_USERDEFINED_MEMORY_17, 4=DEM_DTC_ORIGIN_USERDEFINED_MEMORY_18, 4=DEM_DTC_ORIGIN_USERDEFINED_MEMORY_19, 4=DEM_DTC_ORIGIN_USERDEFINED_MEMORY_1A, 4=DEM_DTC_ORIGIN_USERDEFINED_MEMORY_1B, 4=DEM_DTC_ORIGIN_USERDEFINED_MEMORY_1C, 4=DEM_DTC_ORIGIN_USERDEFINED_MEMORY_1D, 4=DEM_DTC_ORIGIN_USERDEFINED_MEMORY_1E, 4=DEM_DTC_ORIGIN_USERDEFINED_MEMORY_1F, 4=DEM_DTC_ORIGIN_USERDEFINED_MEMORY_20, 4=DEM_DTC_ORIGIN_USERDEFINED_MEMORY_21, 4=DEM_DTC_ORIGIN_USERDEFINED_MEMORY_22, 4=DEM_DTC_ORIGIN_USERDEFINED_MEMORY_23, 4=DEM_DTC_ORIGIN_USERDEFINED_MEMORY_24, 4=DEM_DTC_ORIGIN_USERDEFINED_MEMORY_25, 4=DEM_DTC_ORIGIN_USERDEFINED_MEMORY_26, 4=DEM_DTC_ORIGIN_USERDEFINED_MEMORY_27, 4=DEM_DTC_ORIGIN_USERDEFINED_MEMORY_28, 4=DEM_DTC_ORIGIN_USERDEFINED_MEMORY_29, 4=DEM_DTC_ORIGIN_USERDEFINED_MEMORY_2A, 4=DEM_DTC_ORIGIN_USERDEFINED_MEMORY_2B, 4=DEM_DTC_ORIGIN_USERDEFINED_MEMORY_2C, 4=DEM_DTC_ORIGIN_USERDEFINED_MEMORY_2D, 4=DEM_DTC_ORIGIN_USERDEFINED_MEMORY_2E, 4=DEM_DTC_ORIGIN_USERDEFINED_MEMORY_2F, 4=DEM_DTC_ORIGIN_USERDEFINED_MEMORY_30, 4=DEM_DTC_ORIGIN_USERDEFINED_MEMORY_31, 4=DEM_DTC_ORIGIN_USERDEFINED_MEMORY_32, 4=DEM_DTC_ORIGIN_USERDEFINED_MEMORY_33, 4=DEM_DTC_ORIGIN_USERDEFINED_MEMORY_34, 4=DEM_DTC_ORIGIN_USERDEFINED_MEMORY_35, 4=DEM_DTC_ORIGIN_USERDEFINED_MEMORY_36, 4=DEM_DTC_ORIGIN_USERDEFINED_MEMORY_37, 4=DEM_DTC_ORIGIN_USERDEFINED_MEMORY_38, 4=DEM_DTC_ORIGIN_USERDEFINED_MEMORY_39, 4=DEM_DTC_ORIGIN_USERDEFINED_MEMORY_3A, 4=DEM_DTC_ORIGIN_USERDEFINED_MEMORY_3B, 4=DEM_DTC_ORIGIN_USERDEFINED_MEMORY_3C, 4=DEM_DTC_ORIGIN_USERDEFINED_MEMORY_3D, 4=DEM_DTC_ORIGIN_USERDEFINED_MEMORY_3E, 4=DEM_DTC_ORIGIN_USERDEFINED_MEMORY_3F, 4=DEM_DTC_ORIGIN_USERDEFINED_MEMORY_40, 4=DEM_DTC_ORIGIN_USERDEFINED_MEMORY_41, 4=DEM_DTC_ORIGIN_USERDEFINED_MEMORY_42, 4=DEM_DTC_ORIGIN_USERDEFINED_MEMORY_43, 4=DEM_DTC_ORIGIN_USERDEFINED_MEMORY_44, 4=DEM_DTC_ORIGIN_USERDEFINED_MEMORY_45, 4=DEM_DTC_ORIGIN_USERDEFINED_MEMORY_46, 4=DEM_DTC_ORIGIN_USERDEFINED_MEMORY_47, 4=DEM_DTC_ORIGIN_USERDEFINED_MEMORY_48, 4=DEM_DTC_ORIGIN_USERDEFINED_MEMORY_49, 4=DEM_DTC_ORIGIN_USERDEFINED_MEMORY_4A, 4=DEM_DTC_ORIGIN_USERDEFINED_MEMORY_4B, 4=DEM_DTC_ORIGIN_USERDEFINED_MEMORY_4C, 4=DEM_DTC_ORIGIN_USERDEFINED_MEMORY_4D, 4=DEM_DTC_ORIGIN_USERDEFINED_MEMORY_4E, 4=DEM_DTC_ORIGIN_USERDEFINED_MEMORY_4F, 4=DEM_DTC_ORIGIN_USERDEFINED_MEMORY_50, 4=DEM_DTC_ORIGIN_USERDEFINED_MEMORY_51, 4=DEM_DTC_ORIGIN_USERDEFINED_MEMORY_52, 4=DEM_DTC_ORIGIN_USERDEFINED_MEMORY_53, 4=DEM_DTC_ORIGIN_USERDEFINED_MEMORY_54, 4=DEM_DTC_ORIGIN_USERDEFINED_MEMORY_55, 4=DEM_DTC_ORIGIN_USERDEFINED_MEMORY_56, 4=DEM_DTC_ORIGIN_USERDEFINED_MEMORY_57, 4=DEM_DTC_ORIGIN_USERDEFINED_MEMORY_58, 4=DEM_DTC_ORIGIN_USERDEFINED_MEMORY_59, 4=DEM_DTC_ORIGIN_USERDEFINED_MEMORY_5A, 4=DEM_DTC_ORIGIN_USERDEFINED_MEMORY_5B, 4=DEM_DTC_ORIGIN_USERDEFINED_MEMORY_5C, 4=DEM_DTC_ORIGIN_USERDEFINED_MEMORY_5D, 4=DEM_DTC_ORIGIN_USERDEFINED_MEMORY_5E, 4=DEM_DTC_ORIGIN_USERDEFINED_MEMORY_5F, 4=DEM_DTC_ORIGIN_USERDEFINED_MEMORY_60, 4=DEM_DTC_ORIGIN_USERDEFINED_MEMORY_61, 4=DEM_DTC_ORIGIN_USERDEFINED_MEMORY_62, 4=DEM_DTC_ORIGIN_USERDEFINED_MEMORY_63, 4=DEM_DTC_ORIGIN_USERDEFINED_MEMORY_64, 4=DEM_DTC_ORIGIN_USERDEFINED_MEMORY_65, 4=DEM_DTC_ORIGIN_USERDEFINED_MEMORY_66, 4=DEM_DTC_ORIGIN_USERDEFINED_MEMORY_67, 4=DEM_DTC_ORIGIN_USERDEFINED_MEMORY_68, 4=DEM_DTC_ORIGIN_USERDEFINED_MEMORY_69, 4=DEM_DTC_ORIGIN_USERDEFINED_MEMORY_6A, 4=DEM_DTC_ORIGIN_USERDEFINED_MEMORY_6B, 4=DEM_DTC_ORIGIN_USERDEFINED_MEMORY_6C, 4=DEM_DTC_ORIGIN_USERDEFINED_MEMORY_6D, 4=DEM_DTC_ORIGIN_USERDEFINED_MEMORY_6E, 4=DEM_DTC_ORIGIN_USERDEFINED_MEMORY_6F, 4=DEM_DTC_ORIGIN_USERDEFINED_MEMORY_70, 4=DEM_DTC_ORIGIN_USERDEFINED_MEMORY_71, 4=DEM_DTC_ORIGIN_USERDEFINED_MEMORY_72, 4=DEM_DTC_ORIGIN_USERDEFINED_MEMORY_73, 4=DEM_DTC_ORIGIN_USERDEFINED_MEMORY_74, 4=DEM_DTC_ORIGIN_USERDEFINED_MEMORY_75, 4=DEM_DTC_ORIGIN_USERDEFINED_MEMORY_76, 4=DEM_DTC_ORIGIN_USERDEFINED_MEMORY_77, 4=DEM_DTC_ORIGIN_USERDEFINED_MEMORY_78, 4=DEM_DTC_ORIGIN_USERDEFINED_MEMORY_79, 4=DEM_DTC_ORIGIN_USERDEFINED_MEMORY_7A, 4=DEM_DTC_ORIGIN_USERDEFINED_MEMORY_7B, 4=DEM_DTC_ORIGIN_USERDEFINED_MEMORY_7C, 4=DEM_DTC_ORIGIN_USERDEFINED_MEMORY_7D, 4=DEM_DTC_ORIGIN_USERDEFINED_MEMORY_7E, 4=DEM_DTC_ORIGIN_USERDEFINED_MEMORY_7F, 4=DEM_DTC_ORIGIN_USERDEFINED_MEMORY_80, 4=DEM_DTC_ORIGIN_USERDEFINED_MEMORY_81, 4=DEM_DTC_ORIGIN_USERDEFINED_MEMORY_82, 4=DEM_DTC_ORIGIN_USERDEFINED_MEMORY_83, 4=DEM_DTC_ORIGIN_USERDEFINED_MEMORY_84, 4=DEM_DTC_ORIGIN_USERDEFINED_MEMORY_85, 4=DEM_DTC_ORIGIN_USERDEFINED_MEMORY_86, 4=DEM_DTC_ORIGIN_USERDEFINED_MEMORY_87, 4=DEM_DTC_ORIGIN_USERDEFINED_MEMORY_88, 4=DEM_DTC_ORIGIN_USERDEFINED_MEMORY_89, 4=DEM_DTC_ORIGIN_USERDEFINED_MEMORY_8A, 4=DEM_DTC_ORIGIN_USERDEFINED_MEMORY_8B, 4=DEM_DTC_ORIGIN_USERDEFINED_MEMORY_8C, 4=DEM_DTC_ORIGIN_USERDEFINED_MEMORY_8D, 4=DEM_DTC_ORIGIN_USERDEFINED_MEMORY_8E, 4=DEM_DTC_ORIGIN_USERDEFINED_MEMORY_8F, 4=DEM_DTC_ORIGIN_USERDEFINED_MEMORY_90, 4=DEM_DTC_ORIGIN_USERDEFINED_MEMORY_91, 4=DEM_DTC_ORIGIN_USERDEFINED_MEMORY_92, 4=DEM_DTC_ORIGIN_USERDEFINED_MEMORY_93, 4=DEM_DTC_ORIGIN_USERDEFINED_MEMORY_94, 4=DEM_DTC_ORIGIN_USERDEFINED_MEMORY_95, 4=DEM_DTC_ORIGIN_USERDEFINED_MEMORY_96, 4=DEM_DTC_ORIGIN_USERDEFINED_MEMORY_97, 4=DEM_DTC_ORIGIN_USERDEFINED_MEMORY_98, 4=DEM_DTC_ORIGIN_USERDEFINED_MEMORY_99, 4=DEM_DTC_ORIGIN_USERDEFINED_MEMORY_9A, 4=DEM_DTC_ORIGIN_USERDEFINED_MEMORY_9B, 4=DEM_DTC_ORIGIN_USERDEFINED_MEMORY_9C, 4=DEM_DTC_ORIGIN_USERDEFINED_MEMORY_9D, 4=DEM_DTC_ORIGIN_USERDEFINED_MEMORY_9E, 4=DEM_DTC_ORIGIN_USERDEFINED_MEMORY_9F, 4=DEM_DTC_ORIGIN_USERDEFINED_MEMORY_A0, 4=DEM_DTC_ORIGIN_USERDEFINED_MEMORY_A1, 4=DEM_DTC_ORIGIN_USERDEFINED_MEMORY_A2, 4=DEM_DTC_ORIGIN_USERDEFINED_MEMORY_A3, 4=DEM_DTC_ORIGIN_USERDEFINED_MEMORY_A4, 4=DEM_DTC_ORIGIN_USERDEFINED_MEMORY_A5, 4=DEM_DTC_ORIGIN_USERDEFINED_MEMORY_A6, 4=DEM_DTC_ORIGIN_USERDEFINED_MEMORY_A7, 4=DEM_DTC_ORIGIN_USERDEFINED_MEMORY_A8, 4=DEM_DTC_ORIGIN_USERDEFINED_MEMORY_A9, 4=DEM_DTC_ORIGIN_USERDEFINED_MEMORY_AA, 4=DEM_DTC_ORIGIN_USERDEFINED_MEMORY_AB, 4=DEM_DTC_ORIGIN_USERDEFINED_MEMORY_AC, 4=DEM_DTC_ORIGIN_USERDEFINED_MEMORY_AD, 4=DEM_DTC_ORIGIN_USERDEFINED_MEMORY_AE, 4=DEM_DTC_ORIGIN_USERDEFINED_MEMORY_AF, 4=DEM_DTC_ORIGIN_USERDEFINED_MEMORY_B0, 4=DEM_DTC_ORIGIN_USERDEFINED_MEMORY_B1, 4=DEM_DTC_ORIGIN_USERDEFINED_MEMORY_B2, 4=DEM_DTC_ORIGIN_USERDEFINED_MEMORY_B3, 4=DEM_DTC_ORIGIN_USERDEFINED_MEMORY_B4, 4=DEM_DTC_ORIGIN_USERDEFINED_MEMORY_B5, 4=DEM_DTC_ORIGIN_USERDEFINED_MEMORY_B6, 4=DEM_DTC_ORIGIN_USERDEFINED_MEMORY_B7, 4=DEM_DTC_ORIGIN_USERDEFINED_MEMORY_B8, 4=DEM_DTC_ORIGIN_USERDEFINED_MEMORY_B9, 4=DEM_DTC_ORIGIN_USERDEFINED_MEMORY_BA, 4=DEM_DTC_ORIGIN_USERDEFINED_MEMORY_BB, 4=DEM_DTC_ORIGIN_USERDEFINED_MEMORY_BC, 4=DEM_DTC_ORIGIN_USERDEFINED_MEMORY_BD, 4=DEM_DTC_ORIGIN_USERDEFINED_MEMORY_BE, 4=DEM_DTC_ORIGIN_USERDEFINED_MEMORY_BF, 4=DEM_DTC_ORIGIN_USERDEFINED_MEMORY_C0, 4=DEM_DTC_ORIGIN_USERDEFINED_MEMORY_C1, 4=DEM_DTC_ORIGIN_USERDEFINED_MEMORY_C2, 4=DEM_DTC_ORIGIN_USERDEFINED_MEMORY_C3, 4=DEM_DTC_ORIGIN_USERDEFINED_MEMORY_C4, 4=DEM_DTC_ORIGIN_USERDEFINED_MEMORY_C5, 4=DEM_DTC_ORIGIN_USERDEFINED_MEMORY_C6, 4=DEM_DTC_ORIGIN_USERDEFINED_MEMORY_C7, 4=DEM_DTC_ORIGIN_USERDEFINED_MEMORY_C8, 4=DEM_DTC_ORIGIN_USERDEFINED_MEMORY_C9, 4=DEM_DTC_ORIGIN_USERDEFINED_MEMORY_CA, 4=DEM_DTC_ORIGIN_USERDEFINED_MEMORY_CB, 4=DEM_DTC_ORIGIN_USERDEFINED_MEMORY_CC, 4=DEM_DTC_ORIGIN_USERDEFINED_MEMORY_CD, 4=DEM_DTC_ORIGIN_USERDEFINED_MEMORY_CE, 4=DEM_DTC_ORIGIN_USERDEFINED_MEMORY_CF, 4=DEM_DTC_ORIGIN_USERDEFINED_MEMORY_D0, 4=DEM_DTC_ORIGIN_USERDEFINED_MEMORY_D1, 4=DEM_DTC_ORIGIN_USERDEFINED_MEMORY_D2, 4=DEM_DTC_ORIGIN_USERDEFINED_MEMORY_D3, 4=DEM_DTC_ORIGIN_USERDEFINED_MEMORY_D4, 4=DEM_DTC_ORIGIN_USERDEFINED_MEMORY_D5, 4=DEM_DTC_ORIGIN_USERDEFINED_MEMORY_D6, 4=DEM_DTC_ORIGIN_USERDEFINED_MEMORY_D7, 4=DEM_DTC_ORIGIN_USERDEFINED_MEMORY_D8, 4=DEM_DTC_ORIGIN_USERDEFINED_MEMORY_D9, 4=DEM_DTC_ORIGIN_USERDEFINED_MEMORY_DA, 4=DEM_DTC_ORIGIN_USERDEFINED_MEMORY_DB, 4=DEM_DTC_ORIGIN_USERDEFINED_MEMORY_DC, 4=DEM_DTC_ORIGIN_USERDEFINED_MEMORY_DD, 4=DEM_DTC_ORIGIN_USERDEFINED_MEMORY_DE, 4=DEM_DTC_ORIGIN_USERDEFINED_MEMORY_DF, 4=DEM_DTC_ORIGIN_USERDEFINED_MEMORY_E0, 4=DEM_DTC_ORIGIN_USERDEFINED_MEMORY_E1, 4=DEM_DTC_ORIGIN_USERDEFINED_MEMORY_E2, 4=DEM_DTC_ORIGIN_USERDEFINED_MEMORY_E3, 4=DEM_DTC_ORIGIN_USERDEFINED_MEMORY_E4, 4=DEM_DTC_ORIGIN_USERDEFINED_MEMORY_E5, 4=DEM_DTC_ORIGIN_USERDEFINED_MEMORY_E6, 4=DEM_DTC_ORIGIN_USERDEFINED_MEMORY_E7, 4=DEM_DTC_ORIGIN_USERDEFINED_MEMORY_E8, 4=DEM_DTC_ORIGIN_USERDEFINED_MEMORY_E9, 4=DEM_DTC_ORIGIN_USERDEFINED_MEMORY_EA, 4=DEM_DTC_ORIGIN_USERDEFINED_MEMORY_EB, 4=DEM_DTC_ORIGIN_USERDEFINED_MEMORY_EC, 4=DEM_DTC_ORIGIN_USERDEFINED_MEMORY_ED, 4=DEM_DTC_ORIGIN_USERDEFINED_MEMORY_EE, 4=DEM_DTC_ORIGIN_USERDEFINED_MEMORY_EF, 4=DEM_DTC_ORIGIN_USERDEFINED_MEMORY_F0, 4=DEM_DTC_ORIGIN_USERDEFINED_MEMORY_F1, 4=DEM_DTC_ORIGIN_USERDEFINED_MEMORY_F2, 4=DEM_DTC_ORIGIN_USERDEFINED_MEMORY_F3, 4=DEM_DTC_ORIGIN_USERDEFINED_MEMORY_F4, 4=DEM_DTC_ORIGIN_USERDEFINED_MEMORY_F5, 4=DEM_DTC_ORIGIN_USERDEFINED_MEMORY_F6, 4=DEM_DTC_ORIGIN_USERDEFINED_MEMORY_F7, 4=DEM_DTC_ORIGIN_USERDEFINED_MEMORY_F8, 4=DEM_DTC_ORIGIN_USERDEFINED_MEMORY_F9, 4=DEM_DTC_ORIGIN_USERDEFINED_MEMORY_FA, 4=DEM_DTC_ORIGIN_USERDEFINED_MEMORY_FB, 4=DEM_DTC_ORIGIN_USERDEFINED_MEMORY_FC, 4=DEM_DTC_ORIGIN_USERDEFINED_MEMORY_FD, 4=DEM_DTC_ORIGIN_USERDEFINED_MEMORY_FE, 4=DEM_DTC_ORIGIN_USERDEFINED_MEMORY_FF}, implementation-data-type=uint8
    Dem_DTCFormatType: compu {0=DEM_DTC_FORMAT_OBD, 1=DEM_DTC_FORMAT_UDS, 2=DEM_DTC_FORMAT_J1939}, implementation-data-type=uint8
    Dem_OperationCycleStateType: compu {0=DEM_CYCLE_STATE_START, 1=DEM_CYCLE_STATE_END}, implementation-data-type=uint8
    Dem_IndicatorStatusType: compu {0=DEM_INDICATOR_OFF, 1=DEM_INDICATOR_CONTINUOUS, 2=DEM_INDICATOR_BLINKING, 3=DEM_INDICATOR_BLINK_CONT, 4=DEM_INDICATOR_SLOW_FLASH, 5=DEM_INDICATOR_FAST_FLASH, 6=DEM_INDICATOR_ON_DEMAND, 7=DEM_INDICATOR_SHORT}, implementation-data-type=uint8
    Dem_DTCKindType: compu {1=DEM_DTC_KIND_ALL_DTCS, 2=DEM_DTC_KIND_EMISSION_REL_DTCS}, implementation-data-type=uint8
    Dem_IumprDenomCondIdType: compu {1=DEM_IUMPR_GENERAL_DENOMINATOR, 2=DEM_IUMPR_DEN_COND_COLDSTART, 3=DEM_IUMPR_DEN_COND_EVAP, 4=DEM_IUMPR_DEN_COND_500MI}, implementation-data-type=uint8
    Dem_IumprDenomCondStatusType: compu {0=DEM_IUMPR_DEN_STATUS_NOT_REACHED, 1=DEM_IUMPR_DEN_STATUS_REACHED, 2=DEM_IUMPR_DEN_STATUS_INHIBITED}, implementation-data-type=uint8
    Dem_DebounceResetStatusType: compu {0=DEM_DEBOUNCE_STATUS_FREEZE, 1=DEM_DEBOUNCE_STATUS_RESET}, implementation-data-type=uint8
    Dem_DebouncingStateType: compu {1=DEM_TEMPORARILY_DEFECTIVE, 2=DEM_FINALLY_DEFECTIVE, 4=DEM_TEMPORARILY_HEALED, 8=DEM_TEST_COMPLETE, 16=DEM_DTR_UPDATE}, implementation-data-type=uint8
package /MICROSAR/Dem_swc/Interfaces
  10 x client server interface, all with is-service=true, service-kind=DIAGNOSTIC-EVENT-MANAGER:
    CddIf
      operation ClearDTC: possible-error=[CddIf/DEM_CLEAR_WRONG_DTC, CddIf/DEM_CLEAR_WRONG_DTCORIGIN, CddIf/DEM_CLEAR_FAILED, CddIf/DEM_CLEAR_PENDING, CddIf/DEM_CLEAR_BUSY, CddIf/DEM_CLEAR_MEMORY_ERROR]
        arg DTC: type=uint32, direction=IN
        arg DTCFormat: type=Dem_DTCFormatType, direction=IN
        arg DTCOrigin: type=Dem_DTCOriginType, direction=IN
      6 x error:
        DEM_CLEAR_WRONG_DTC: error-code=1
        DEM_CLEAR_WRONG_DTCORIGIN: error-code=2
        DEM_CLEAR_FAILED: error-code=3
        DEM_CLEAR_PENDING: error-code=4
        DEM_CLEAR_BUSY: error-code=5
        DEM_CLEAR_MEMORY_ERROR: error-code=6
    DemServices
      operation GetPostRunRequested: possible-error=DemServices/E_NOT_OK
        arg IsRequested: type=boolean, direction=OUT
      operation GetDTCStatusAvailabilityMask: possible-error=DemServices/E_NOT_OK
        arg DTCStatusMask: type=uint8, direction=OUT
      error E_NOT_OK: error-code=1
    GeneralDiagnosticInfo
      9 x operation:
        GetEventStatus: possible-error=GeneralDiagnosticInfo/E_NOT_OK
          arg EventId: type=Dem_EventIdType, direction=IN
          arg EventStatusExtended: type=Dem_EventStatusExtendedType, direction=OUT
        GetEventFailed: possible-error=GeneralDiagnosticInfo/E_NOT_OK
          arg EventId: type=Dem_EventIdType, direction=IN
          arg EventFailed: type=boolean, direction=OUT
        GetEventTested: possible-error=GeneralDiagnosticInfo/E_NOT_OK
          arg EventId: type=Dem_EventIdType, direction=IN
          arg EventTested: type=boolean, direction=OUT
        GetDTCOfEvent: possible-error=[GeneralDiagnosticInfo/E_NOT_OK, GeneralDiagnosticInfo/DEM_E_NO_DTC_AVAILABLE]
          arg EventId: type=Dem_EventIdType, direction=IN
          arg DTCFormat: type=Dem_DTCFormatType, direction=IN
          arg DTCOfEvent: type=uint32, direction=OUT
        GetFaultDetectionCounter: possible-error=[GeneralDiagnosticInfo/E_NOT_OK, GeneralDiagnosticInfo/DEM_E_NO_FDC_AVAILABLE]
          arg EventId: type=Dem_EventIdType, direction=IN
          arg FaultDetectionCounter: type=sint8, direction=OUT
        GetEventFreezeFrameData: possible-error=[GeneralDiagnosticInfo/E_NOT_OK, GeneralDiagnosticInfo/DEM_E_NODATAAVAILABLE, GeneralDiagnosticInfo/DEM_E_WRONG_RECORDNUMBER, GeneralDiagnosticInfo/DEM_E_WRONG_DIDNUMBER]
          5 x arg:
            EventId: type=Dem_EventIdType, direction=IN
            RecordNumber: type=uint8, direction=IN
            ReportTotalRecord: type=boolean, direction=IN
            DataId: type=uint16, direction=IN
            DestBuffer: type=Dem_MaxDataValueType, direction=OUT
        GetEventExtendedDataRecord: possible-error=[GeneralDiagnosticInfo/E_NOT_OK, GeneralDiagnosticInfo/DEM_E_NODATAAVAILABLE, GeneralDiagnosticInfo/DEM_E_WRONG_RECORDNUMBER]
          arg EventId: type=Dem_EventIdType, direction=IN
          arg RecordNumber: type=uint8, direction=IN
          arg DestBuffer: type=Dem_MaxDataValueType, direction=OUT
        GetEventEnableCondition: possible-error=GeneralDiagnosticInfo/E_NOT_OK
          arg EventId: type=Dem_EventIdType, direction=IN
          arg ConditionFullfilled: type=boolean, direction=OUT
        GetDebouncingOfEvent: possible-error=GeneralDiagnosticInfo/E_NOT_OK
          arg EventId: type=Dem_EventIdType, direction=IN
          arg DebouncingState: type=Dem_DebouncingStateType, direction=OUT
      6 x error:
        E_NOT_OK: error-code=1
        DEM_E_NO_DTC_AVAILABLE: error-code=2
        DEM_E_NO_FDC_AVAILABLE: error-code=3
        DEM_E_NODATAAVAILABLE: error-code=48
        DEM_E_WRONG_RECORDNUMBER: error-code=49
        DEM_E_WRONG_DIDNUMBER: error-code=50
    DiagnosticInfo
      9 x operation:
        GetEventStatus: possible-error=DiagnosticInfo/E_NOT_OK
          arg EventStatusExtended: type=Dem_EventStatusExtendedType, direction=OUT
        GetEventFailed: possible-error=DiagnosticInfo/E_NOT_OK
          arg EventFailed: type=boolean, direction=OUT
        GetEventTested: possible-error=DiagnosticInfo/E_NOT_OK
          arg EventTested: type=boolean, direction=OUT
        GetDTCOfEvent: possible-error=[DiagnosticInfo/E_NOT_OK, DiagnosticInfo/DEM_E_NO_DTC_AVAILABLE]
          arg DTCFormat: type=Dem_DTCFormatType, direction=IN
          arg DTCOfEvent: type=uint32, direction=OUT
        GetFaultDetectionCounter: possible-error=[DiagnosticInfo/E_NOT_OK, DiagnosticInfo/DEM_E_NO_FDC_AVAILABLE]
          arg FaultDetectionCounter: type=sint8, direction=OUT
        GetEventFreezeFrameData: possible-error=[DiagnosticInfo/E_NOT_OK, DiagnosticInfo/DEM_E_NODATAAVAILABLE, DiagnosticInfo/DEM_E_WRONG_RECORDNUMBER, DiagnosticInfo/DEM_E_WRONG_DIDNUMBER]
          4 x arg:
            RecordNumber: type=uint8, direction=IN
            ReportTotalRecord: type=boolean, direction=IN
            DataId: type=uint16, direction=IN
            DestBuffer: type=Dem_MaxDataValueType, direction=OUT
        GetEventExtendedDataRecord: possible-error=[DiagnosticInfo/E_NOT_OK, DiagnosticInfo/DEM_E_NODATAAVAILABLE, DiagnosticInfo/DEM_E_WRONG_RECORDNUMBER]
          arg RecordNumber: type=uint8, direction=IN
          arg DestBuffer: type=Dem_MaxDataValueType, direction=OUT
        GetEventEnableCondition: possible-error=DiagnosticInfo/E_NOT_OK
          arg ConditionFullfilled: type=boolean, direction=OUT
        GetDebouncingOfEvent: possible-error=DiagnosticInfo/E_NOT_OK
          arg DebouncingState: type=Dem_DebouncingStateType, direction=OUT
      6 x error:
        E_NOT_OK: error-code=1
        DEM_E_NO_DTC_AVAILABLE: error-code=2
        DEM_E_NO_FDC_AVAILABLE: error-code=3
        DEM_E_NODATAAVAILABLE: error-code=48
        DEM_E_WRONG_RECORDNUMBER: error-code=49
        DEM_E_WRONG_DIDNUMBER: error-code=50
    DiagnosticMonitor
      10 x operation:
        SetEventStatus: possible-error=DiagnosticMonitor/E_NOT_OK
          arg EventStatus: type=Dem_EventStatusType, direction=IN
        ResetEventStatus: possible-error=DiagnosticMonitor/E_NOT_OK
        ResetEventDebounceStatus: possible-error=DiagnosticMonitor/E_NOT_OK
          arg DebounceResetStatus: type=Dem_DebounceResetStatusType, direction=IN
        GetEventStatus: possible-error=DiagnosticMonitor/E_NOT_OK
          arg EventStatusExtended: type=Dem_EventStatusExtendedType, direction=OUT
        GetEventFailed: possible-error=DiagnosticMonitor/E_NOT_OK
          arg EventFailed: type=boolean, direction=OUT
        GetEventTested: possible-error=DiagnosticMonitor/E_NOT_OK
          arg EventTested: type=boolean, direction=OUT
        GetDTCOfEvent: possible-error=[DiagnosticMonitor/E_NOT_OK, DiagnosticMonitor/DEM_E_NO_DTC_AVAILABLE]
          arg DTCFormat: type=Dem_DTCFormatType, direction=IN
          arg DTCOfEvent: type=uint32, direction=OUT
        GetFaultDetectionCounter: possible-error=[DiagnosticMonitor/E_NOT_OK, DiagnosticMonitor/DEM_E_NO_FDC_AVAILABLE]
          arg FaultDetectionCounter: type=sint8, direction=OUT
        GetEventFreezeFrameData: possible-error=[DiagnosticMonitor/E_NOT_OK, DiagnosticMonitor/DEM_E_NODATAAVAILABLE, DiagnosticMonitor/DEM_E_WRONG_RECORDNUMBER, DiagnosticMonitor/DEM_E_WRONG_DIDNUMBER]
          4 x arg:
            RecordNumber: type=uint8, direction=IN
            ReportTotalRecord: type=boolean, direction=IN
            DataId: type=uint16, direction=IN
            DestBuffer: type=Dem_MaxDataValueType, direction=OUT
        GetEventExtendedDataRecord: possible-error=[DiagnosticMonitor/E_NOT_OK, DiagnosticMonitor/DEM_E_NODATAAVAILABLE, DiagnosticMonitor/DEM_E_WRONG_RECORDNUMBER]
          arg RecordNumber: type=uint8, direction=IN
          arg DestBuffer: type=Dem_MaxDataValueType, direction=OUT
      6 x error:
        E_NOT_OK: error-code=1
        DEM_E_NO_DTC_AVAILABLE: error-code=2
        DEM_E_NO_FDC_AVAILABLE: error-code=3
        DEM_E_NODATAAVAILABLE: error-code=48
        DEM_E_WRONG_RECORDNUMBER: error-code=49
        DEM_E_WRONG_DIDNUMBER: error-code=50
    DcmIf
      5 x operation:
        DcmClearDTC: possible-error=[DcmIf/DEM_CLEAR_WRONG_DTC, DcmIf/DEM_CLEAR_WRONG_DTCORIGIN, DcmIf/DEM_CLEAR_FAILED, DcmIf/DEM_CLEAR_PENDING, DcmIf/DEM_CLEAR_BUSY, DcmIf/DEM_CLEAR_MEMORY_ERROR]
          arg DTC: type=uint32, direction=IN
          arg DTCFormat: type=Dem_DTCFormatType, direction=IN
          arg DTCOrigin: type=Dem_DTCOriginType, direction=IN
        DcmGetNextFilteredDTCAndFDC: possible-error=DEM_FILTERED_NO_MATCHING_DTC
          arg DTC: type=uint32, direction=OUT
          arg DTCFaultDetectionCounter: type=sint8, direction=OUT
        DcmEnableDTCSetting: possible-error=[DEM_CONTROL_DTC_SETTING_N_OK, DEM_CONTROL_DTC_WRONG_DTCGROUP]
          arg DTCGroup: type=Dem_DTCGroupType, direction=IN
          arg DTCKind: type=Dem_DTCKindType, direction=IN
        DcmGetFreezeFrameDataByDTC: possible-error=[DEM_GET_FFDATABYDTC_WRONG_DTC, DEM_GET_FFDATABYDTC_WRONG_DTCORIGIN, DEM_GET_FFDATABYDTC_WRONG_RECORDNUMBER, DEM_GET_FFDATABYDTC_WRONG_BUFFERSIZE, DEM_GET_FFDATABYDTC_PENDING]
          5 x arg:
            DTC: type=uint32, direction=IN
            DTCOrigin: type=Dem_DTCOriginType, direction=IN
            RecordNumber: type=uint8, direction=IN
            DestBuffer: type=uint8, direction=OUT
            BufSize: type=uint16, direction=INOUT
        DcmGetExtendedDataRecordByDTC: possible-error=[DEM_RECORD_WRONG_DTC, DEM_RECORD_WRONG_DTCORIGIN, DEM_RECORD_WRONG_NUMBER, DEM_RECORD_WRONG_BUFFERSIZE, DEM_RECORD_PENDING]
          5 x arg:
            DTC: type=uint32, direction=IN
            DTCOrigin: type=Dem_DTCOriginType, direction=IN
            ExtendedDataNumber: type=uint8, direction=IN
            DestBuffer: type=uint8, direction=OUT
            BufSize: type=uint16, direction=INOUT
      19 x error:
        DEM_CLEAR_WRONG_DTC: error-code=1
        DEM_CONTROL_DTC_SETTING_N_OK: error-code=1
        DEM_FILTERED_NO_MATCHING_DTC: error-code=1
        DEM_GET_FFDATABYDTC_WRONG_DTC: error-code=1
        DEM_RECORD_WRONG_DTC: error-code=1
        DEM_CLEAR_WRONG_DTCORIGIN: error-code=2
        DEM_CONTROL_DTC_WRONG_DTCGROUP: error-code=2
        DEM_GET_FFDATABYDTC_WRONG_DTCORIGIN: error-code=2
        DEM_RECORD_WRONG_DTCORIGIN: error-code=2
        DEM_CLEAR_FAILED: error-code=3
        DEM_GET_FFDATABYDTC_WRONG_RECORDNUMBER: error-code=3
        DEM_RECORD_WRONG_NUMBER: error-code=3
        DEM_CLEAR_PENDING: error-code=4
        DEM_GET_FFDATABYDTC_WRONG_BUFFERSIZE: error-code=4
        DEM_RECORD_WRONG_BUFFERSIZE: error-code=4
        DEM_CLEAR_BUSY: error-code=5
        DEM_GET_FFDATABYDTC_PENDING: error-code=5
        DEM_RECORD_PENDING: error-code=5
        DEM_CLEAR_MEMORY_ERROR: error-code=6
    OperationCycle
      operation SetOperationCycleState: possible-error=OperationCycle/E_NOT_OK
        arg CycleState: type=Dem_OperationCycleStateType, direction=IN
      error E_NOT_OK: error-code=1
    GeneralCallbackEventStatusChange
      operation EventStatusChanged
        arg EventId: type=Dem_EventIdType, direction=IN
        arg EventStatusOld: type=Dem_EventStatusExtendedType, direction=IN
        arg EventStatusNew: type=Dem_EventStatusExtendedType, direction=IN
    EvMemOverflowIndication
      operation GetEventMemoryOverflow: possible-error=EvMemOverflowIndication/E_NOT_OK
        arg OverflowIndication: type=boolean, direction=OUT
      operation GetNumberOfEventMemoryEntries: possible-error=EvMemOverflowIndication/E_NOT_OK
        arg NumberOfEventMemoryEntries: type=uint8, direction=OUT
      error E_NOT_OK: error-code=1
    EnableCondition
      operation SetEnableCondition: possible-error=EnableCondition/E_NOT_OK
        arg ConditionFulfilled: type=boolean, direction=IN
      error E_NOT_OK: error-code=1
